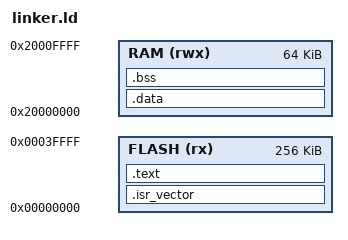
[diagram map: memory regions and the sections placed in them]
MEMORY
{
  FLASH (rx)  : ORIGIN = 0x00000000, LENGTH = 256K
  RAM   (rwx) : ORIGIN = 0x20000000, LENGTH = 64K
}

SECTIONS
{
  .isr_vector : {
    KEEP(*(.isr_vector))
  } > FLASH

  .text : {
    *(.text*)
    *(.rodata*)
  } > FLASH

  .data : {
    *(.data*)
  } > RAM

  .bss : {
    *(.bss*)
    *(COMMON)
    end = .;
    _end = .;
  } > RAM
}
